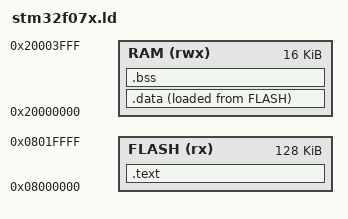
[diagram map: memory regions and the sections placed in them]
MEMORY
{
    FLASH (rx) : ORIGIN = 0x08000000, LENGTH = 128K
    RAM (rwx) : ORIGIN = 0x20000000, LENGTH = 16K
}

ENTRY(Reset_Handler)

SECTIONS
{
    .text :
    {
        *(.isr_vector)
        *(.text)
        *(.text.*)
        *(.rodata)
        *(.rodata.*)
        . = ALIGN(4);
        _etext = .;
    } > FLASH

    /* The start address of the data segment in flash */
    _sidata = LOADADDR(.data);

    .data :
    {
        _sdata = .;
        *(.data)
        *(.data.*)
        . = ALIGN(4);
        _edata = .;
    } > RAM AT > FLASH

    .bss :
    {
        _sbss = .;
        *(.bss)
        *(.bss.*)
        *(COMMON)
        . = ALIGN(4);
        _ebss = .;
        end = .;
        __end__ = .;
    } > RAM

    _estack = ORIGIN(RAM) + LENGTH(RAM);
}
